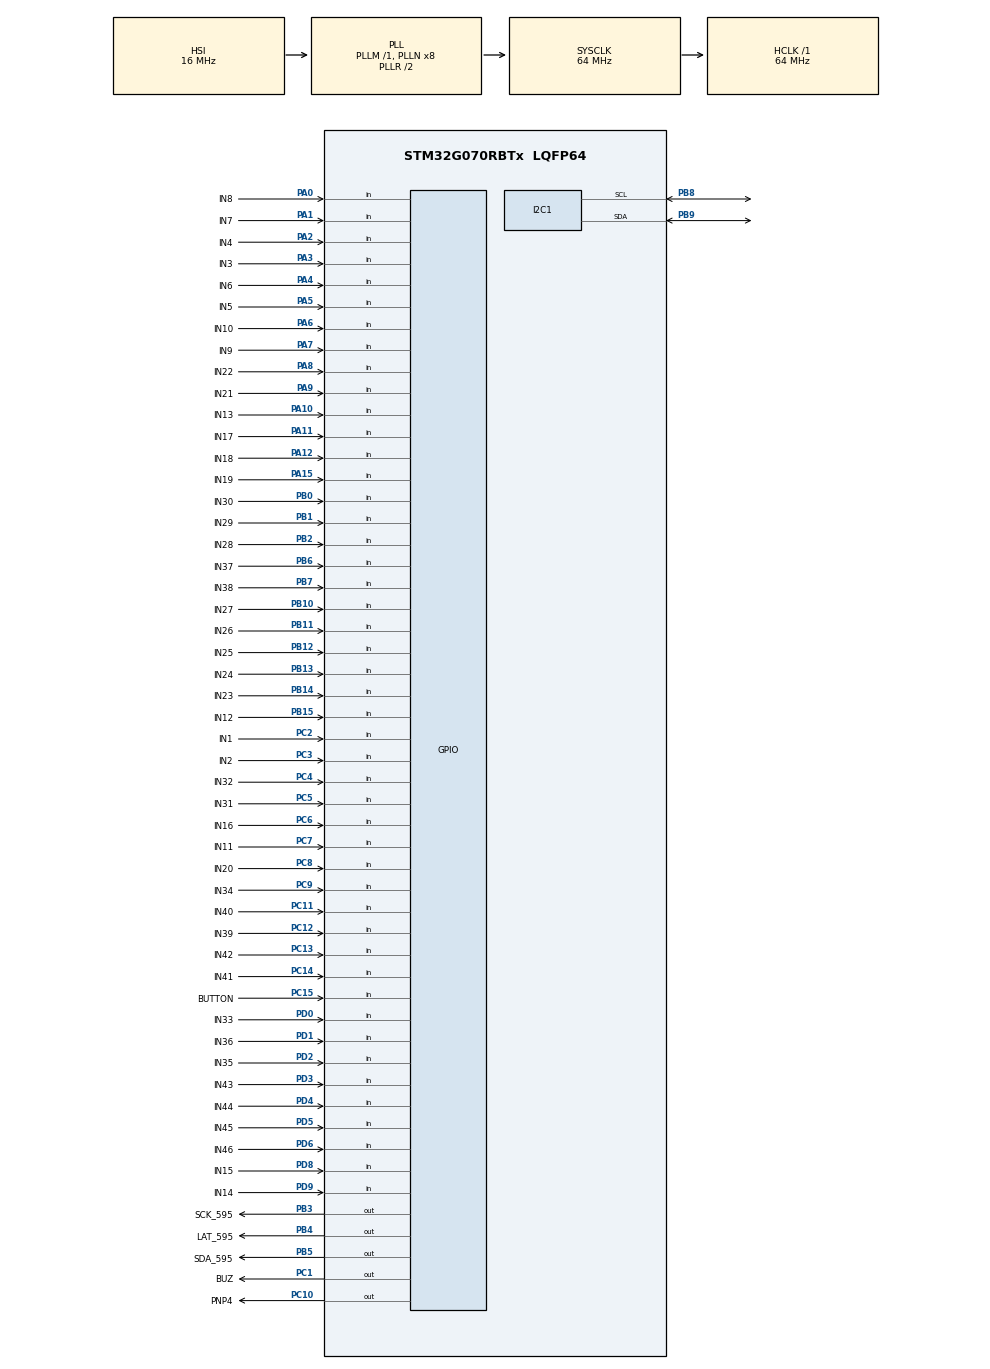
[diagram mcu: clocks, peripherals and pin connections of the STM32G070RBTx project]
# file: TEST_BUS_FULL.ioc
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I2C1.CustomTiming=Enabled
I2C1.Timing=0x10707DBC
IWDG.Prescaler=IWDG_PRESCALER_32
Mcu.Family=STM32G0
Mcu.Name=STM32G070RBTx
Mcu.Package=LQFP64
NVIC.I2C1_IRQn=true\:0\:0\:false\:false\:true\:true\:true\:true
PA0.GPIO_Label=IN8
PA0.GPIO_PuPd=GPIO_PULLUP
PA0.Signal=GPIO_Input
PA1.GPIO_Label=IN7
PA1.GPIO_PuPd=GPIO_PULLUP
PA1.Signal=GPIO_Input
PA10.GPIO_Label=IN13
PA10.GPIO_PuPd=GPIO_PULLUP
PA10.Signal=GPIO_Input
PA11\ [PA9].GPIO_Label=IN17
PA11\ [PA9].GPIO_PuPd=GPIO_PULLUP
PA11\ [PA9].Signal=GPIO_Input
PA12\ [PA10].GPIO_Label=IN18
PA12\ [PA10].GPIO_PuPd=GPIO_PULLUP
PA12\ [PA10].Signal=GPIO_Input
PA13.Mode=Serial_Wire
PA13.Signal=SYS_SWDIO
PA14-BOOT0.Mode=Serial_Wire
PA14-BOOT0.Signal=SYS_SWCLK
PA15.GPIO_Label=IN19
PA15.GPIO_PuPd=GPIO_PULLUP
PA15.Signal=GPIO_Input
PA2.GPIO_Label=IN4
PA2.GPIO_PuPd=GPIO_PULLUP
PA2.Signal=GPIO_Input
PA3.GPIO_Label=IN3
PA3.GPIO_PuPd=GPIO_PULLUP
PA3.Signal=GPIO_Input
PA4.GPIO_Label=IN6
PA4.GPIO_PuPd=GPIO_PULLUP
PA4.Signal=GPIO_Input
PA5.GPIO_Label=IN5
PA5.GPIO_PuPd=GPIO_PULLUP
PA5.Signal=GPIO_Input
PA6.GPIO_Label=IN10
PA6.GPIO_PuPd=GPIO_PULLUP
PA6.Signal=GPIO_Input
PA7.GPIO_Label=IN9
PA7.GPIO_PuPd=GPIO_PULLUP
PA7.Signal=GPIO_Input
PA8.GPIO_Label=IN22
PA8.GPIO_PuPd=GPIO_PULLUP
PA8.Signal=GPIO_Input
PA9.GPIO_Label=IN21
PA9.GPIO_PuPd=GPIO_PULLUP
PA9.Signal=GPIO_Input
PB0.GPIO_Label=IN30
PB0.GPIO_PuPd=GPIO_PULLUP
PB0.Signal=GPIO_Input
PB1.GPIO_Label=IN29
PB1.GPIO_PuPd=GPIO_PULLUP
PB1.Signal=GPIO_Input
PB10.GPIO_Label=IN27
PB10.GPIO_PuPd=GPIO_PULLUP
PB10.Signal=GPIO_Input
PB11.GPIO_Label=IN26
PB11.GPIO_PuPd=GPIO_PULLUP
PB11.Signal=GPIO_Input
PB12.GPIO_Label=IN25
PB12.GPIO_PuPd=GPIO_PULLUP
PB12.Signal=GPIO_Input
PB13.GPIO_Label=IN24
PB13.GPIO_PuPd=GPIO_PULLUP
PB13.Signal=GPIO_Input
PB14.GPIO_Label=IN23
PB14.GPIO_PuPd=GPIO_PULLUP
PB14.Signal=GPIO_Input
PB15.GPIO_Label=IN12
PB15.GPIO_PuPd=GPIO_PULLUP
PB15.Signal=GPIO_Input
PB2.GPIO_Label=IN28
PB2.GPIO_PuPd=GPIO_PULLUP
PB2.Signal=GPIO_Input
PB3.GPIO_Label=SCK_595
PB3.GPIO_PuPd=GPIO_PULLUP
PB3.GPIO_Speed=GPIO_SPEED_FREQ_VERY_HIGH
PB3.Signal=GPIO_Output
PB4.GPIO_Label=LAT_595
PB4.GPIO_ModeDefaultOutputPP=GPIO_MODE_OUTPUT_PP
PB4.GPIO_PuPd=GPIO_PULLUP
PB4.GPIO_Speed=GPIO_SPEED_FREQ_VERY_HIGH
PB4.PinState=GPIO_PIN_RESET
PB4.Signal=GPIO_Output
PB5.GPIO_Label=SDA_595
PB5.GPIO_PuPd=GPIO_PULLUP
PB5.GPIO_Speed=GPIO_SPEED_FREQ_VERY_HIGH
PB5.Signal=GPIO_Output
PB6.GPIO_Label=IN37
PB6.GPIO_PuPd=GPIO_PULLUP
PB6.Signal=GPIO_Input
PB7.GPIO_Label=IN38
PB7.GPIO_PuPd=GPIO_PULLUP
PB7.Signal=GPIO_Input
PB8.GPIO_Pu=GPIO_PULLUP
PB8.Mode=I2C
PB8.Signal=I2C1_SCL
PB9.GPIO_Pu=GPIO_PULLUP
PB9.GPIO_Speed=GPIO_SPEED_FREQ_HIGH
PB9.Mode=I2C
PB9.Signal=I2C1_SDA
PC1.GPIO_Label=BUZ
PC1.GPIO_PuPd=GPIO_PULLDOWN
PC1.GPIO_Speed=GPIO_SPEED_FREQ_MEDIUM
PC1.Signal=GPIO_Output
PC10.GPIO_Label=PNP4
PC10.GPIO_ModeDefaultOutputPP=GPIO_MODE_OUTPUT_OD
PC10.GPIO_PuPd=GPIO_PULLUP
PC10.Signal=GPIO_Output
PC11.GPIO_Label=IN40
PC11.GPIO_PuPd=GPIO_PULLUP
PC11.Signal=GPIO_Input
PC12.GPIO_Label=IN39
PC12.GPIO_PuPd=GPIO_PULLUP
PC12.Signal=GPIO_Input
PC13.GPIO_Label=IN42
PC13.GPIO_PuPd=GPIO_PULLUP
PC13.Signal=GPIO_Input
PC14-OSC32_IN\ (PC14).GPIO_Label=IN41
PC14-OSC32_IN\ (PC14).GPIO_PuPd=GPIO_PULLUP
PC14-OSC32_IN\ (PC14).Signal=GPIO_Input
PC15-OSC32_OUT\ (PC15).GPIO_Label=BUTTON
PC15-OSC32_OUT\ (PC15).GPIO_PuPd=GPIO_PULLUP
PC15-OSC32_OUT\ (PC15).Signal=GPIO_Input
PC2.GPIO_Label=IN1
PC2.GPIO_PuPd=GPIO_PULLUP
PC2.Signal=GPIO_Input
PC3.GPIO_Label=IN2
PC3.GPIO_PuPd=GPIO_PULLUP
PC3.Signal=GPIO_Input
PC4.GPIO_Label=IN32
PC4.GPIO_PuPd=GPIO_PULLUP
PC4.Signal=GPIO_Input
PC5.GPIO_Label=IN31
PC5.GPIO_PuPd=GPIO_PULLUP
PC5.Signal=GPIO_Input
PC6.GPIO_Label=IN16
PC6.GPIO_PuPd=GPIO_PULLUP
PC6.Signal=GPIO_Input
PC7.GPIO_Label=IN11
PC7.GPIO_PuPd=GPIO_PULLUP
PC7.Signal=GPIO_Input
PC8.GPIO_Label=IN20
PC8.GPIO_PuPd=GPIO_PULLUP
PC8.Signal=GPIO_Input
PC9.GPIO_Label=IN34
PC9.GPIO_PuPd=GPIO_PULLUP
PC9.Signal=GPIO_Input
PD0.GPIO_Label=IN33
PD0.GPIO_PuPd=GPIO_PULLUP
PD0.Signal=GPIO_Input
PD1.GPIO_Label=IN36
PD1.GPIO_PuPd=GPIO_PULLUP
PD1.Signal=GPIO_Input
PD2.GPIO_Label=IN35
PD2.GPIO_PuPd=GPIO_PULLUP
PD2.Signal=GPIO_Input
PD3.GPIO_Label=IN43
PD3.GPIO_PuPd=GPIO_PULLUP
PD3.Signal=GPIO_Input
PD4.GPIO_Label=IN44
PD4.GPIO_PuPd=GPIO_PULLUP
PD4.Signal=GPIO_Input
PD5.GPIO_Label=IN45
PD5.GPIO_PuPd=GPIO_PULLUP
PD5.Signal=GPIO_Input
PD6.GPIO_Label=IN46
PD6.GPIO_PuPd=GPIO_PULLUP
PD6.Signal=GPIO_Input
PD8.GPIO_Label=IN15
PD8.GPIO_PuPd=GPIO_PULLUP
PD8.Signal=GPIO_Input
PD9.GPIO_Label=IN14
PD9.GPIO_PuPd=GPIO_PULLUP
PD9.Signal=GPIO_Input
ProjectManager.HeapSize=0x200
ProjectManager.StackSize=0x400
ProjectManager.TargetToolchain=STM32CubeIDE
RCC.ADCCLockSelection=RCC_ADCCLKSOURCE_HSI
RCC.ADCFreq_Value=16000000
RCC.AHBFreq_Value=64000000
RCC.CortexFreq_Value=64000000
RCC.EXTERNAL_CLOCK_VALUE=48000
RCC.HCLKFreq_Value=64000000
RCC.HSE_VALUE=8000000
RCC.HSI_VALUE=16000000
RCC.LSE_VALUE=32768
RCC.SYSCLKFreq_VALUE=64000000
RCC.SYSCLKSource=RCC_SYSCLKSOURCE_PLLCLK
RCC.VCOOutputFreq_Value=128000000
VP_IWDG_VS_IWDG.Mode=IWDG_Activate
VP_SYS_VS_DBSignals.Mode=DisableDeadBatterySignals
board=custom

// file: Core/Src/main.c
/* USER CODE BEGIN Header */
/**
 ******************************************************************************
 * @file           : main.c
 * @brief          : Main program body
 ******************************************************************************
 * @attention
 *
 * <h2><center>&copy; Copyright (c) 2020 STMicroelectronics.
 * All rights reserved.</center></h2>
 *
 * This software component is licensed by ST under BSD 3-Clause license,
 * the "License"; You may not use this file except in compliance with the
 * License. You may obtain a copy of the License at:
 *                        opensource.org/licenses/BSD-3-Clause
 *
 ******************************************************************************
 */
/* USER CODE END Header */
#include "main.h"

/* USER CODE BEGIN Includes */
#include "myHeader.h"
/* USER CODE END Includes */

I2C_HandleTypeDef hi2c1;

IWDG_HandleTypeDef hiwdg;

void SystemClock_Config(void);
static void MX_GPIO_Init(void);
static void MX_I2C1_Init(void);
static void MX_IWDG_Init(void);

int main(void)
{

  /* MCU Configuration--------------------------------------------------------*/

  /* Reset of all peripherals, Initializes the Flash interface and the Systick. */
  HAL_Init();

  /* Configure the system clock */
  SystemClock_Config();

  /* Initialize all configured peripherals */
  MX_GPIO_Init();
  MX_I2C1_Init();
  MX_IWDG_Init();
  /* USER CODE BEGIN 2 */
  test_bus_init();
  //test_595(1);

  /* USER CODE END 2 */

  /* Infinite loop */
  /* USER CODE BEGIN WHILE */
  HAL_IWDG_Init(&hiwdg);
  while (1)
  {
    HAL_IWDG_Refresh(&hiwdg);
    /* USER CODE END WHILE */

    /* USER CODE BEGIN 3 */
    test_bus_loop();

  }
  /* USER CODE END 3 */
}

void SystemClock_Config(void)
{
  RCC_OscInitTypeDef RCC_OscInitStruct = {0};
  RCC_ClkInitTypeDef RCC_ClkInitStruct = {0};

  /** Configure the main internal regulator output voltage
  */
  HAL_PWREx_ControlVoltageScaling(PWR_REGULATOR_VOLTAGE_SCALE1);

  /** Initializes the RCC Oscillators according to the specified parameters
  * in the RCC_OscInitTypeDef structure.
  */
  RCC_OscInitStruct.OscillatorType = RCC_OSCILLATORTYPE_HSI|RCC_OSCILLATORTYPE_LSI;
  RCC_OscInitStruct.HSIState = RCC_HSI_ON;
  RCC_OscInitStruct.HSIDiv = RCC_HSI_DIV1;
  RCC_OscInitStruct.HSICalibrationValue = RCC_HSICALIBRATION_DEFAULT;
  RCC_OscInitStruct.LSIState = RCC_LSI_ON;
  RCC_OscInitStruct.PLL.PLLState = RCC_PLL_ON;
  RCC_OscInitStruct.PLL.PLLSource = RCC_PLLSOURCE_HSI;
  RCC_OscInitStruct.PLL.PLLM = RCC_PLLM_DIV1;
  RCC_OscInitStruct.PLL.PLLN = 8;
  RCC_OscInitStruct.PLL.PLLP = RCC_PLLP_DIV2;
  RCC_OscInitStruct.PLL.PLLR = RCC_PLLR_DIV2;
  if (HAL_RCC_OscConfig(&RCC_OscInitStruct) != HAL_OK)
  {
    Error_Handler();
  }

  /** Initializes the CPU, AHB and APB buses clocks
  */
  RCC_ClkInitStruct.ClockType = RCC_CLOCKTYPE_HCLK|RCC_CLOCKTYPE_SYSCLK
                              |RCC_CLOCKTYPE_PCLK1;
  RCC_ClkInitStruct.SYSCLKSource = RCC_SYSCLKSOURCE_PLLCLK;
  RCC_ClkInitStruct.AHBCLKDivider = RCC_SYSCLK_DIV1;
  RCC_ClkInitStruct.APB1CLKDivider = RCC_HCLK_DIV1;

  if (HAL_RCC_ClockConfig(&RCC_ClkInitStruct, FLASH_LATENCY_2) != HAL_OK)
  {
    Error_Handler();
  }
}

static void MX_I2C1_Init(void)
{

  hi2c1.Instance = I2C1;
  hi2c1.Init.Timing = 0x10707DBC;
  hi2c1.Init.OwnAddress1 = 0;
  hi2c1.Init.AddressingMode = I2C_ADDRESSINGMODE_7BIT;
  hi2c1.Init.DualAddressMode = I2C_DUALADDRESS_DISABLE;
  hi2c1.Init.OwnAddress2 = 0;
  hi2c1.Init.OwnAddress2Masks = I2C_OA2_NOMASK;
  hi2c1.Init.GeneralCallMode = I2C_GENERALCALL_DISABLE;
  hi2c1.Init.NoStretchMode = I2C_NOSTRETCH_DISABLE;
  if (HAL_I2C_Init(&hi2c1) != HAL_OK)
  {
    Error_Handler();
  }

  /** Configure Analogue filter
  */
  if (HAL_I2CEx_ConfigAnalogFilter(&hi2c1, I2C_ANALOGFILTER_ENABLE) != HAL_OK)
  {
    Error_Handler();
  }

  /** Configure Digital filter
  */
  if (HAL_I2CEx_ConfigDigitalFilter(&hi2c1, 0) != HAL_OK)
  {
    Error_Handler();
  }

}

static void MX_IWDG_Init(void)
{

  hiwdg.Instance = IWDG;
  hiwdg.Init.Prescaler = IWDG_PRESCALER_32;
  hiwdg.Init.Window = 4095;
  hiwdg.Init.Reload = 4095;
  if (HAL_IWDG_Init(&hiwdg) != HAL_OK)
  {
    Error_Handler();
  }

}

static void MX_GPIO_Init(void)
{
  GPIO_InitTypeDef GPIO_InitStruct = {0};

  /* GPIO Ports Clock Enable */
  __HAL_RCC_GPIOC_CLK_ENABLE();
  __HAL_RCC_GPIOA_CLK_ENABLE();
  __HAL_RCC_GPIOB_CLK_ENABLE();
  __HAL_RCC_GPIOD_CLK_ENABLE();

  /*Configure GPIO pin Output Level */
  HAL_GPIO_WritePin(GPIOC, BUZ_Pin|PNP4_Pin, GPIO_PIN_RESET);

  /*Configure GPIO pin Output Level */
  HAL_GPIO_WritePin(GPIOB, SCK_595_Pin|LAT_595_Pin|SDA_595_Pin, GPIO_PIN_RESET);

  /*Configure GPIO pins : IN40_Pin IN39_Pin IN42_Pin IN41_Pin
                           BUTTON_Pin IN1_Pin IN2_Pin IN32_Pin
                           IN31_Pin IN16_Pin IN11_Pin IN20_Pin
                           IN34_Pin */
  GPIO_InitStruct.Pin = IN40_Pin|IN39_Pin|IN42_Pin|IN41_Pin
                          |BUTTON_Pin|IN1_Pin|IN2_Pin|IN32_Pin
                          |IN31_Pin|IN16_Pin|IN11_Pin|IN20_Pin
                          |IN34_Pin;
  GPIO_InitStruct.Mode = GPIO_MODE_INPUT;
  GPIO_InitStruct.Pull = GPIO_PULLUP;
  HAL_GPIO_Init(GPIOC, &GPIO_InitStruct);

  /*Configure GPIO pin : BUZ_Pin */
  GPIO_InitStruct.Pin = BUZ_Pin;
  GPIO_InitStruct.Mode = GPIO_MODE_OUTPUT_PP;
  GPIO_InitStruct.Pull = GPIO_PULLDOWN;
  GPIO_InitStruct.Speed = GPIO_SPEED_FREQ_MEDIUM;
  HAL_GPIO_Init(BUZ_GPIO_Port, &GPIO_InitStruct);

  /*Configure GPIO pins : IN8_Pin IN7_Pin IN4_Pin IN3_Pin
                           IN6_Pin IN5_Pin IN10_Pin IN9_Pin
                           IN22_Pin IN21_Pin IN13_Pin IN17_Pin
                           IN18_Pin IN19_Pin */
  GPIO_InitStruct.Pin = IN8_Pin|IN7_Pin|IN4_Pin|IN3_Pin
                          |IN6_Pin|IN5_Pin|IN10_Pin|IN9_Pin
                          |IN22_Pin|IN21_Pin|IN13_Pin|IN17_Pin
                          |IN18_Pin|IN19_Pin;
  GPIO_InitStruct.Mode = GPIO_MODE_INPUT;
  GPIO_InitStruct.Pull = GPIO_PULLUP;
  HAL_GPIO_Init(GPIOA, &GPIO_InitStruct);

  /*Configure GPIO pins : IN30_Pin IN29_Pin IN28_Pin IN27_Pin
                           IN26_Pin IN25_Pin IN24_Pin IN23_Pin
                           IN12_Pin IN37_Pin IN38_Pin */
  GPIO_InitStruct.Pin = IN30_Pin|IN29_Pin|IN28_Pin|IN27_Pin
                          |IN26_Pin|IN25_Pin|IN24_Pin|IN23_Pin
                          |IN12_Pin|IN37_Pin|IN38_Pin;
  GPIO_InitStruct.Mode = GPIO_MODE_INPUT;
  GPIO_InitStruct.Pull = GPIO_PULLUP;
  HAL_GPIO_Init(GPIOB, &GPIO_InitStruct);

  /*Configure GPIO pins : IN15_Pin IN14_Pin IN33_Pin IN36_Pin
                           IN35_Pin IN43_Pin IN44_Pin IN45_Pin
                           IN46_Pin */
  GPIO_InitStruct.Pin = IN15_Pin|IN14_Pin|IN33_Pin|IN36_Pin
                          |IN35_Pin|IN43_Pin|IN44_Pin|IN45_Pin
                          |IN46_Pin;
  GPIO_InitStruct.Mode = GPIO_MODE_INPUT;
  GPIO_InitStruct.Pull = GPIO_PULLUP;
  HAL_GPIO_Init(GPIOD, &GPIO_InitStruct);

  /*Configure GPIO pins : SCK_595_Pin LAT_595_Pin SDA_595_Pin */
  GPIO_InitStruct.Pin = SCK_595_Pin|LAT_595_Pin|SDA_595_Pin;
  GPIO_InitStruct.Mode = GPIO_MODE_OUTPUT_PP;
  GPIO_InitStruct.Pull = GPIO_PULLUP;
  GPIO_InitStruct.Speed = GPIO_SPEED_FREQ_VERY_HIGH;
  HAL_GPIO_Init(GPIOB, &GPIO_InitStruct);

  /*Configure GPIO pin : PNP4_Pin */
  GPIO_InitStruct.Pin = PNP4_Pin;
  GPIO_InitStruct.Mode = GPIO_MODE_OUTPUT_OD;
  GPIO_InitStruct.Pull = GPIO_PULLUP;
  GPIO_InitStruct.Speed = GPIO_SPEED_FREQ_LOW;
  HAL_GPIO_Init(PNP4_GPIO_Port, &GPIO_InitStruct);

}

void Error_Handler(void)
{
}
